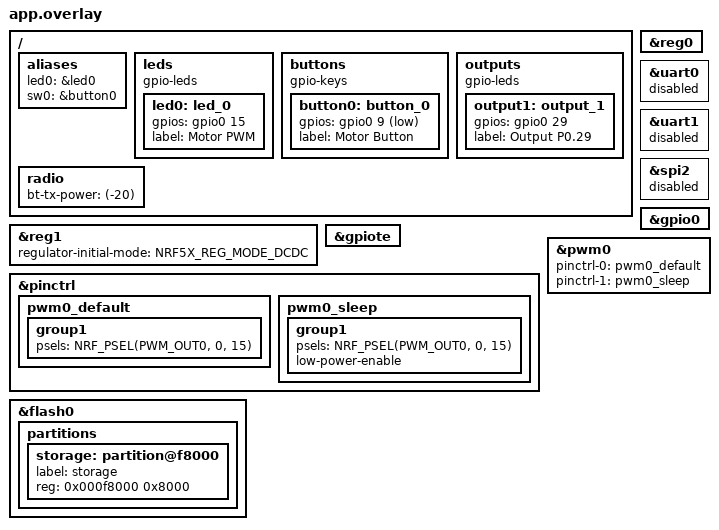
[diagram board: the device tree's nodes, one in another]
/ {
    aliases {
        led0 = &led0;
        sw0 = &button0;
    };

    leds {
        compatible = "gpio-leds";
        led0: led_0 {
            gpios = <&gpio0 15 GPIO_ACTIVE_HIGH>;
            label = "Motor PWM";
        };
    };

    buttons {
        compatible = "gpio-keys";
        button0: button_0 {
            gpios = <&gpio0 9 (GPIO_PULL_UP | GPIO_ACTIVE_LOW)>;
            label = "Motor Button";
        };
    };

    outputs {
        compatible = "gpio-leds";
        output1: output_1 {
            gpios = <&gpio0 29 GPIO_ACTIVE_HIGH>; 
            label = "Output P0.29";
        };
    };

    radio{
        bt-tx-power = <(-20)>;
    }; 

};

&reg1 {
    status = "okay";
    regulator-initial-mode = <NRF5X_REG_MODE_DCDC>;
};

&reg0 {
    status = "okay";
};

/* ОБЯЗАТЕЛЬНО отключить UART для сна */
&uart0 {
    status = "disabled";
};

/* Отключить UARTE1 */
&uart1 {
    status = "disabled";
};

/* Отключить SPI2 */
&spi2 {
    status = "disabled";
};

&gpio0 {
    status = "okay";
};

&gpiote {
    status = "okay";
};

&pinctrl {
    pwm0_default: pwm0_default {
        group1 {
            psels = <NRF_PSEL(PWM_OUT0, 0, 15)>;
        };
    };

    pwm0_sleep: pwm0_sleep {
        group1 {
            psels = <NRF_PSEL(PWM_OUT0, 0, 15)>;
            low-power-enable;
        };
    };
};

&pwm0 {
    status = "okay";
    pinctrl-0 = <&pwm0_default>;
    pinctrl-1 = <&pwm0_sleep>;
    pinctrl-names = "default", "sleep";
};

&flash0 {
    partitions {
        /* Правильный синтаксис: partition@ + адрес из reg */
        storage: partition@f8000 {
            label = "storage";
            reg = <0x000f8000 0x8000>;   /* 32 КБ в конце flash */
        };
    };
};

/*
Общий размер: 1024 KB (0x100000 байт)

0x00000000  ┌──────────────────────────────┐
            │ MBR (4 KB)                   │ Мастер загрузчик
0x00001000  ├──────────────────────────────┤
            │ SoftDevice (если используется)│
0x00027000  ├──────────────────────────────┤ (пример)
            │                              │
            │ Application Code             │
            │ (~960 KB доступно)           │
            │                              │
            │                              │
0x000F8000  ├──────────────────────────────┤ ← Ваш NVS раздел начинается здесь
            │ NVS Storage (32 KB)          │
            │  - Sector 0 (4 KB) 0xF8000   │
            │  - Sector 1 (4 KB) 0xF9000   │
            │  - Sector 2 (4 KB) 0xFA000   │
            │  - Sector 3 (4 KB) 0xFB000   │
            │  - Sector 4 (4 KB) 0xFC000   │
            │  - Sector 5 (4 KB) 0xFD000   │
            │  - Sector 6 (4 KB) 0xFE000   │
            │  - Sector 7 (4 KB) 0xFF000   │
0x00100000  └──────────────────────────────┘
*/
